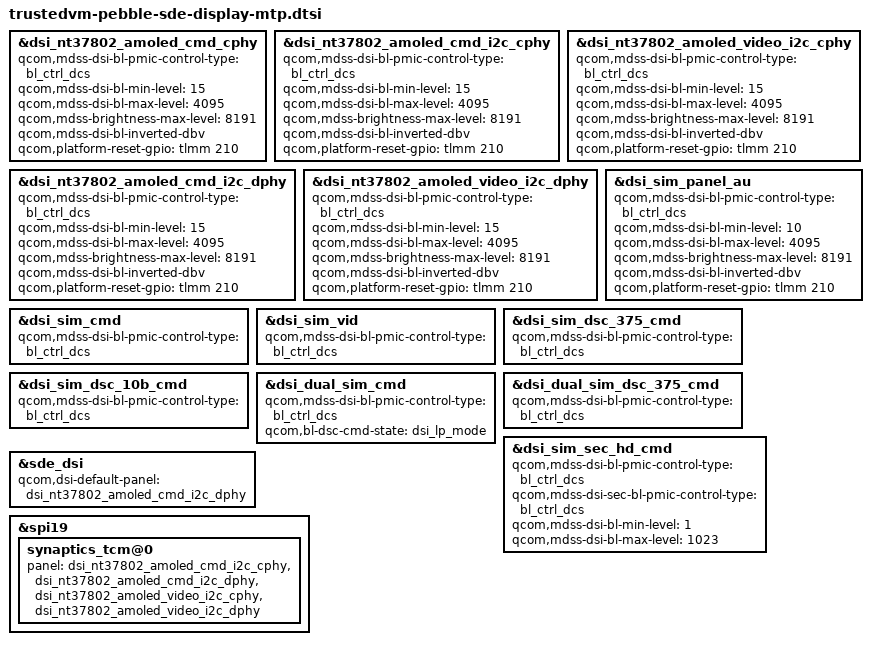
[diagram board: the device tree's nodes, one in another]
// SPDX-License-Identifier: BSD-3-Clause
/*
 * Copyright (c) Qualcomm Technologies, Inc. and/or its subsidiaries.
 */

#include "trustedvm-pebble-sde-display.dtsi"

&dsi_nt37802_amoled_cmd_cphy {
	qcom,mdss-dsi-bl-pmic-control-type = "bl_ctrl_dcs";
	qcom,mdss-dsi-bl-min-level = <15>;
	qcom,mdss-dsi-bl-max-level = <4095>;
	qcom,mdss-brightness-max-level = <8191>;
	qcom,mdss-dsi-bl-inverted-dbv;
	qcom,platform-reset-gpio = <&tlmm 210 0>;
};

&dsi_nt37802_amoled_cmd_i2c_cphy {
	qcom,mdss-dsi-bl-pmic-control-type = "bl_ctrl_dcs";
	qcom,mdss-dsi-bl-min-level = <15>;
	qcom,mdss-dsi-bl-max-level = <4095>;
	qcom,mdss-brightness-max-level = <8191>;
	qcom,mdss-dsi-bl-inverted-dbv;
	qcom,platform-reset-gpio = <&tlmm 210 0>;
};

&dsi_nt37802_amoled_video_i2c_cphy {
	qcom,mdss-dsi-bl-pmic-control-type = "bl_ctrl_dcs";
	qcom,mdss-dsi-bl-min-level = <15>;
	qcom,mdss-dsi-bl-max-level = <4095>;
	qcom,mdss-brightness-max-level = <8191>;
	qcom,mdss-dsi-bl-inverted-dbv;
	qcom,platform-reset-gpio = <&tlmm 210 0>;
};

&dsi_nt37802_amoled_cmd_i2c_dphy {
	qcom,mdss-dsi-bl-pmic-control-type = "bl_ctrl_dcs";
	qcom,mdss-dsi-bl-min-level = <15>;
	qcom,mdss-dsi-bl-max-level = <4095>;
	qcom,mdss-brightness-max-level = <8191>;
	qcom,mdss-dsi-bl-inverted-dbv;
	qcom,platform-reset-gpio = <&tlmm 210 0>;
};

&dsi_nt37802_amoled_video_i2c_dphy {
	qcom,mdss-dsi-bl-pmic-control-type = "bl_ctrl_dcs";
	qcom,mdss-dsi-bl-min-level = <15>;
	qcom,mdss-dsi-bl-max-level = <4095>;
	qcom,mdss-brightness-max-level = <8191>;
	qcom,mdss-dsi-bl-inverted-dbv;
	qcom,platform-reset-gpio = <&tlmm 210 0>;
};

&dsi_sim_panel_au {
	qcom,mdss-dsi-bl-pmic-control-type = "bl_ctrl_dcs";
	qcom,mdss-dsi-bl-min-level = <10>;
	qcom,mdss-dsi-bl-max-level = <4095>;
	qcom,mdss-brightness-max-level = <8191>;
	qcom,mdss-dsi-bl-inverted-dbv;
	qcom,platform-reset-gpio = <&tlmm 210 0>;
};

&dsi_sim_cmd {
	qcom,mdss-dsi-bl-pmic-control-type = "bl_ctrl_dcs";
};

&dsi_sim_vid {
	qcom,mdss-dsi-bl-pmic-control-type = "bl_ctrl_dcs";
};

&dsi_sim_dsc_375_cmd {
	qcom,mdss-dsi-bl-pmic-control-type = "bl_ctrl_dcs";
};

&dsi_sim_dsc_10b_cmd {
	qcom,mdss-dsi-bl-pmic-control-type = "bl_ctrl_dcs";
};

&dsi_dual_sim_cmd {
	qcom,mdss-dsi-bl-pmic-control-type = "bl_ctrl_dcs";
	qcom,bl-dsc-cmd-state = "dsi_lp_mode";
};

&dsi_dual_sim_dsc_375_cmd {
	qcom,mdss-dsi-bl-pmic-control-type = "bl_ctrl_dcs";
};

&dsi_sim_sec_hd_cmd {
	qcom,mdss-dsi-bl-pmic-control-type = "bl_ctrl_dcs";
	qcom,mdss-dsi-sec-bl-pmic-control-type = "bl_ctrl_dcs";
	qcom,mdss-dsi-bl-min-level = <1>;
	qcom,mdss-dsi-bl-max-level = <1023>;
};

&sde_dsi {
	qcom,dsi-default-panel = <&dsi_nt37802_amoled_cmd_i2c_dphy>;
};

&spi19 {
	synaptics_tcm@0 {
		panel = <&dsi_nt37802_amoled_cmd_i2c_cphy
			&dsi_nt37802_amoled_cmd_i2c_dphy
			&dsi_nt37802_amoled_video_i2c_cphy
			&dsi_nt37802_amoled_video_i2c_dphy>;
	};
};
